# hib1p2 register map
Vendor: Texas Instruments
Peripheral module from a debugger description file (folder cc32).
Registers are 32-bit, read-write, no defined reset value unless marked. A register's access mark holds for its fields unless they carry their own. Offsets are as the file gives them; lines under a group give offsets from that group; [hi:lo] are bit positions; {n}, {i} and the like mark numbered series; 'fields as' and 'values as' point back to an identical list; <NAME> marks a mode.

## hib1p2
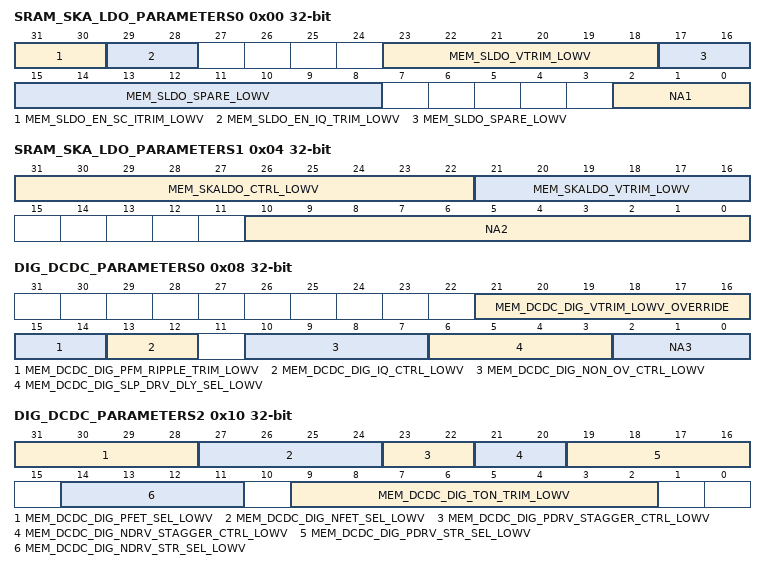
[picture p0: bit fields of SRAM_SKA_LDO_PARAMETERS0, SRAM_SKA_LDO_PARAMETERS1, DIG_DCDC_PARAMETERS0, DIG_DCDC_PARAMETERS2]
0x00 SRAM_SKA_LDO_PARAMETERS0
  [31:30] MEM_SLDO_EN_SC_ITRIM_LOWV, [29:28] MEM_SLDO_EN_IQ_TRIM_LOWV, [23:18] MEM_SLDO_VTRIM_LOWV, [17:8] MEM_SLDO_SPARE_LOWV, [2:0] NA1
0x04 SRAM_SKA_LDO_PARAMETERS1
  [31:22] MEM_SKALDO_CTRL_LOWV, [21:16] MEM_SKALDO_VTRIM_LOWV, [10:0] NA2
0x08 DIG_DCDC_PARAMETERS0
  [21:16] MEM_DCDC_DIG_VTRIM_LOWV_OVERRIDE — Override value for DCDC_DIG_VTRIM : Applicable only when bit [27] of DIG_DCDC_PARAMETERS1 [0x000C] is set to 1.
  [15:14] MEM_DCDC_DIG_PFM_RIPPLE_TRIM_LOWV
  [13:12] MEM_DCDC_DIG_IQ_CTRL_LOWV
  [10:7] MEM_DCDC_DIG_NON_OV_CTRL_LOWV
  [6:3] MEM_DCDC_DIG_SLP_DRV_DLY_SEL_LOWV
  [2:0] NA3
0x0C DIG_DCDC_PARAMETERS1
  [24:0] NA4
0x10 DIG_DCDC_PARAMETERS2
  [31:28] MEM_DCDC_DIG_PFET_SEL_LOWV, [27:24] MEM_DCDC_DIG_NFET_SEL_LOWV, [23:22] MEM_DCDC_DIG_PDRV_STAGGER_CTRL_LOWV, [21:20] MEM_DCDC_DIG_NDRV_STAGGER_CTRL_LOWV, [19:16] MEM_DCDC_DIG_PDRV_STR_SEL_LOWV, [14:11] MEM_DCDC_DIG_NDRV_STR_SEL_LOWV, [9:2] MEM_DCDC_DIG_TON_TRIM_LOWV
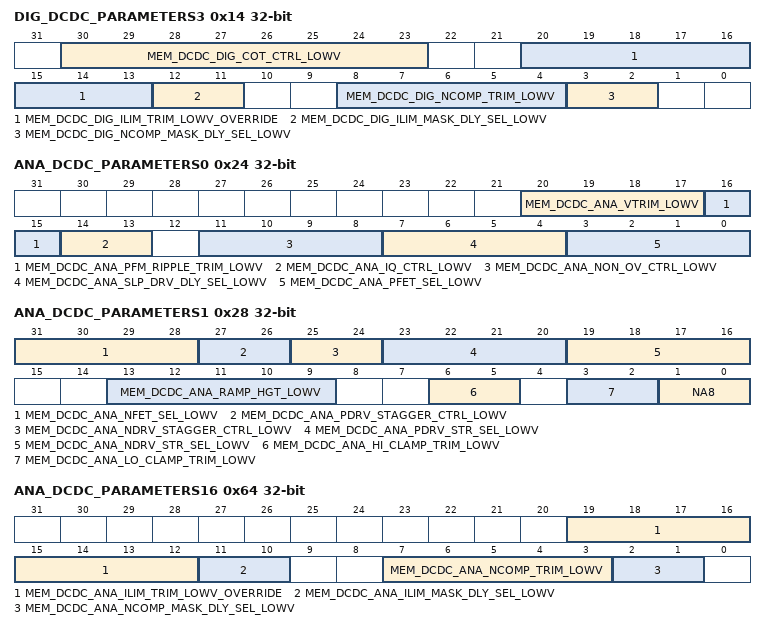
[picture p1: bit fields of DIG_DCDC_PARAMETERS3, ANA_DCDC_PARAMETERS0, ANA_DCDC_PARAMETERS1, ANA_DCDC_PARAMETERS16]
0x14 DIG_DCDC_PARAMETERS3
  [30:23] MEM_DCDC_DIG_COT_CTRL_LOWV
  [20:13] MEM_DCDC_DIG_ILIM_TRIM_LOWV_OVERRIDE — Override value for DCDC_DIG_ILIM_TRIM : Applicable only when bit [25] of DIG_DCDC_PARAMETERS1 [0x000C] is set to 1
  [12:11] MEM_DCDC_DIG_ILIM_MASK_DLY_SEL_LOWV
  [8:4] MEM_DCDC_DIG_NCOMP_TRIM_LOWV
  [3:2] MEM_DCDC_DIG_NCOMP_MASK_DLY_SEL_LOWV
0x18 DIG_DCDC_PARAMETERS4
  [28:0] NA7
0x1C DIG_DCDC_PARAMETERS5 access not given
0x20 DIG_DCDC_PARAMETERS6 access not given
0x24 ANA_DCDC_PARAMETERS0
  [20:17] MEM_DCDC_ANA_VTRIM_LOWV, [16:15] MEM_DCDC_ANA_PFM_RIPPLE_TRIM_LOWV, [14:13] MEM_DCDC_ANA_IQ_CTRL_LOWV, [11:8] MEM_DCDC_ANA_NON_OV_CTRL_LOWV, [7:4] MEM_DCDC_ANA_SLP_DRV_DLY_SEL_LOWV, [3:0] MEM_DCDC_ANA_PFET_SEL_LOWV
0x28 ANA_DCDC_PARAMETERS1
  [31:28] MEM_DCDC_ANA_NFET_SEL_LOWV, [27:26] MEM_DCDC_ANA_PDRV_STAGGER_CTRL_LOWV, [25:24] MEM_DCDC_ANA_NDRV_STAGGER_CTRL_LOWV, [23:20] MEM_DCDC_ANA_PDRV_STR_SEL_LOWV, [19:16] MEM_DCDC_ANA_NDRV_STR_SEL_LOWV, [13:9] MEM_DCDC_ANA_RAMP_HGT_LOWV, [6:5] MEM_DCDC_ANA_HI_CLAMP_TRIM_LOWV, [3:2] MEM_DCDC_ANA_LO_CLAMP_TRIM_LOWV, [1:0] NA8
0x64 ANA_DCDC_PARAMETERS16
  [19:12] MEM_DCDC_ANA_ILIM_TRIM_LOWV_OVERRIDE, [11:10] MEM_DCDC_ANA_ILIM_MASK_DLY_SEL_LOWV, [7:3] MEM_DCDC_ANA_NCOMP_TRIM_LOWV, [2:1] MEM_DCDC_ANA_NCOMP_MASK_DLY_SEL_LOWV
0x68 ANA_DCDC_PARAMETERS17
  [29:0] NA17
0x6C ANA_DCDC_PARAMETERS18 access not given
0x70 ANA_DCDC_PARAMETERS19 access not given
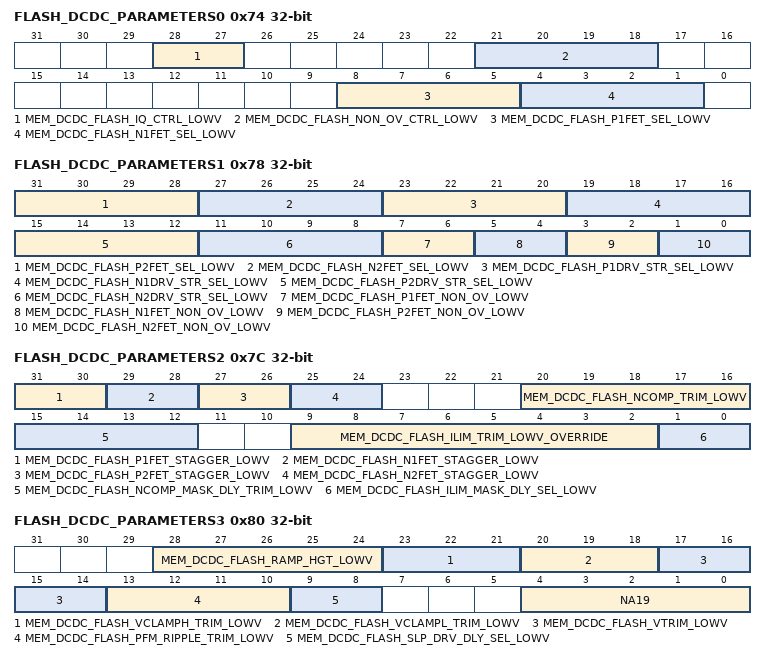
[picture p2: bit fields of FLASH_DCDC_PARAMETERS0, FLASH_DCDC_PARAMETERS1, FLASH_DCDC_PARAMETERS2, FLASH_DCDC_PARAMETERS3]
0x74 FLASH_DCDC_PARAMETERS0
  [28:27] MEM_DCDC_FLASH_IQ_CTRL_LOWV, [21:18] MEM_DCDC_FLASH_NON_OV_CTRL_LOWV, [8:5] MEM_DCDC_FLASH_P1FET_SEL_LOWV, [4:1] MEM_DCDC_FLASH_N1FET_SEL_LOWV
0x78 FLASH_DCDC_PARAMETERS1
  [31:28] MEM_DCDC_FLASH_P2FET_SEL_LOWV, [27:24] MEM_DCDC_FLASH_N2FET_SEL_LOWV, [23:20] MEM_DCDC_FLASH_P1DRV_STR_SEL_LOWV, [19:16] MEM_DCDC_FLASH_N1DRV_STR_SEL_LOWV, [15:12] MEM_DCDC_FLASH_P2DRV_STR_SEL_LOWV, [11:8] MEM_DCDC_FLASH_N2DRV_STR_SEL_LOWV, [7:6] MEM_DCDC_FLASH_P1FET_NON_OV_LOWV, [5:4] MEM_DCDC_FLASH_N1FET_NON_OV_LOWV, [3:2] MEM_DCDC_FLASH_P2FET_NON_OV_LOWV, [1:0] MEM_DCDC_FLASH_N2FET_NON_OV_LOWV
0x7C FLASH_DCDC_PARAMETERS2
  [31:30] MEM_DCDC_FLASH_P1FET_STAGGER_LOWV, [29:28] MEM_DCDC_FLASH_N1FET_STAGGER_LOWV, [27:26] MEM_DCDC_FLASH_P2FET_STAGGER_LOWV, [25:24] MEM_DCDC_FLASH_N2FET_STAGGER_LOWV, [20:16] MEM_DCDC_FLASH_NCOMP_TRIM_LOWV, [15:12] MEM_DCDC_FLASH_NCOMP_MASK_DLY_TRIM_LOWV, [9:2] MEM_DCDC_FLASH_ILIM_TRIM_LOWV_OVERRIDE, [1:0] MEM_DCDC_FLASH_ILIM_MASK_DLY_SEL_LOWV
0x80 FLASH_DCDC_PARAMETERS3
  [28:24] MEM_DCDC_FLASH_RAMP_HGT_LOWV, [23:21] MEM_DCDC_FLASH_VCLAMPH_TRIM_LOWV, [20:18] MEM_DCDC_FLASH_VCLAMPL_TRIM_LOWV, [17:14] MEM_DCDC_FLASH_VTRIM_LOWV, [13:10] MEM_DCDC_FLASH_PFM_RIPPLE_TRIM_LOWV, [9:8] MEM_DCDC_FLASH_SLP_DRV_DLY_SEL_LOWV, [4:0] NA19
0x84 FLASH_DCDC_PARAMETERS4 access not given
0x88 FLASH_DCDC_PARAMETERS5 access not given
0x8C FLASH_DCDC_PARAMETERS6
  [29:0] NA20
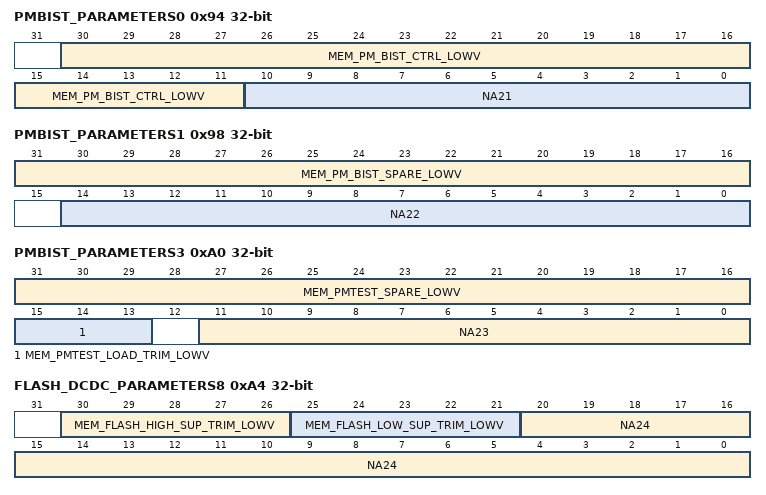
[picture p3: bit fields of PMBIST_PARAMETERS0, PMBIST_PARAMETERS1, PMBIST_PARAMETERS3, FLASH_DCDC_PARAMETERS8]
0x94 PMBIST_PARAMETERS0
  [30:11] MEM_PM_BIST_CTRL_LOWV, [10:0] NA21
0x98 PMBIST_PARAMETERS1
  [31:16] MEM_PM_BIST_SPARE_LOWV, [14:0] NA22
0x9C PMBIST_PARAMETERS2 access not given
0xA0 PMBIST_PARAMETERS3
  [31:16] MEM_PMTEST_SPARE_LOWV, [15:13] MEM_PMTEST_LOAD_TRIM_LOWV, [11:0] NA23
0xA4 FLASH_DCDC_PARAMETERS8
  [30:26] MEM_FLASH_HIGH_SUP_TRIM_LOWV, [25:21] MEM_FLASH_LOW_SUP_TRIM_LOWV, [20:0] NA24
0xA8 ANA_DCDC_PARAMETERS_OVERRIDE access not given
0xAC FLASH_DCDC_PARAMETERS_OVERRIDE access not given
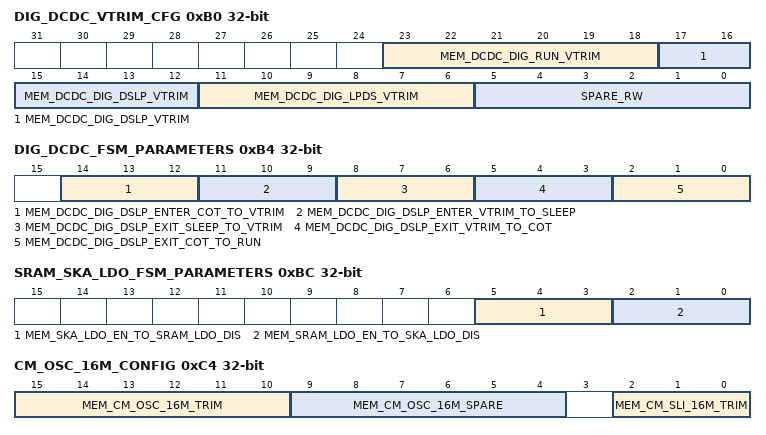
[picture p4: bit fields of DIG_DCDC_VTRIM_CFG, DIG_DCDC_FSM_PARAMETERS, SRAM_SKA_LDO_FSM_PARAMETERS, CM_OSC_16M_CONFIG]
0xB0 DIG_DCDC_VTRIM_CFG
  [23:18] MEM_DCDC_DIG_RUN_VTRIM, [17:12] MEM_DCDC_DIG_DSLP_VTRIM, [11:6] MEM_DCDC_DIG_LPDS_VTRIM, [5:0] SPARE_RW
0xB4 DIG_DCDC_FSM_PARAMETERS
  [14:12] MEM_DCDC_DIG_DSLP_ENTER_COT_TO_VTRIM, [11:9] MEM_DCDC_DIG_DSLP_ENTER_VTRIM_TO_SLEEP, [8:6] MEM_DCDC_DIG_DSLP_EXIT_SLEEP_TO_VTRIM, [5:3] MEM_DCDC_DIG_DSLP_EXIT_VTRIM_TO_COT, [2:0] MEM_DCDC_DIG_DSLP_EXIT_COT_TO_RUN
0xB8 ANA_DCDC_FSM_PARAMETERS
  [2:0] MEM_DCDC_ANA_DSLP_EXIT_SLEEP_TO_RUN
0xBC SRAM_SKA_LDO_FSM_PARAMETERS
  [5:3] MEM_SKA_LDO_EN_TO_SRAM_LDO_DIS, [2:0] MEM_SRAM_LDO_EN_TO_SKA_LDO_DIS
0xC0 BGAP_DUTY_CYCLING_EXIT_CFG
  [2:0] MEM_BGAP_DUTY_CYCLING_EXIT_TIME
0xC4 CM_OSC_16M_CONFIG
  [15:10] MEM_CM_OSC_16M_TRIM, [9:4] MEM_CM_OSC_16M_SPARE, [2:0] MEM_CM_SLI_16M_TRIM
0xC8 SOP_SENSE_VALUE
  [7:0] SOP_SENSE_VALUE
0xCC HIB_RTC_TIMER_LSW_1P2 access not given
0xD0 HIB_RTC_TIMER_MSW_1P2
  [15:0] HIB_RTC_TIMER_MSW
0xD4 BGAP_TRIM_OVERRIDES access not given
0xD8 EFUSE_READ_REG0 access not given
0xDC EFUSE_READ_REG1 access not given
0xE0 POR_TEST_CTRL access not given
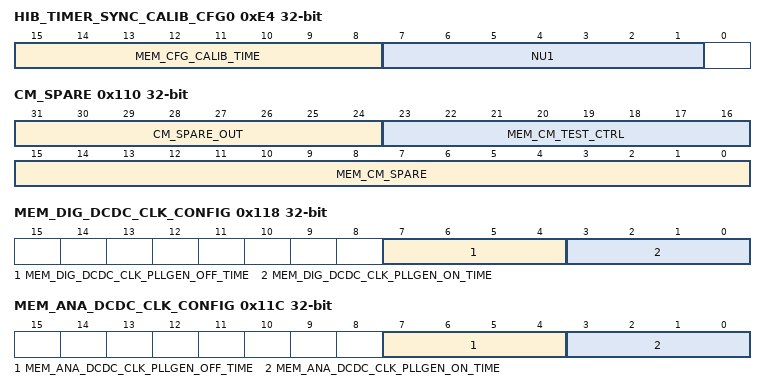
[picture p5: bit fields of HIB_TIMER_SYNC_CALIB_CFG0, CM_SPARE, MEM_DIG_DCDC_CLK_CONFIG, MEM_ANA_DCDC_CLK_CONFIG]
0xE4 HIB_TIMER_SYNC_CALIB_CFG0
  [15:8] MEM_CFG_CALIB_TIME, [7:1] NU1
0xE8 HIB_TIMER_SYNC_CALIB_CFG1
  [19:0] FAST_CALIB_COUNT
0xEC HIB_TIMER_SYNC_CFG2
  [7:2] NU1
0xF0 HIB_TIMER_SYNC_TSF_ADJ_VAL access not given
0xF4 HIB_TIMER_RTC_GTS_TIMESTAMP_LSW access not given
0xF8 HIB_TIMER_RTC_GTS_TIMESTAMP_MSW
  [15:0] RTC_GTS_TIMESTAMP_MSW
0xFC HIB_TIMER_RTC_WUP_TIMESTAMP_LSW access not given
0x100 HIB_TIMER_RTC_WUP_TIMESTAMP_MSW
  [15:0] RTC_WUP_TIMESTAMP_MSW
0x104 HIB_TIMER_SYNC_WAKE_OFFSET_ERR
  [11:0] WUP_OFFSET_ERROR
0x108 HIB_TIMER_SYNC_TSF_CURR_VAL_LSW access not given
0x10C HIB_TIMER_SYNC_TSF_CURR_VAL_MSW access not given
0x110 CM_SPARE
  [31:24] CM_SPARE_OUT, [23:16] MEM_CM_TEST_CTRL, [15:0] MEM_CM_SPARE
0x114 PORPOL_SPARE access not given
0x118 MEM_DIG_DCDC_CLK_CONFIG
  [7:4] MEM_DIG_DCDC_CLK_PLLGEN_OFF_TIME, [3:0] MEM_DIG_DCDC_CLK_PLLGEN_ON_TIME
0x11C MEM_ANA_DCDC_CLK_CONFIG
  [7:4] MEM_ANA_DCDC_CLK_PLLGEN_OFF_TIME, [3:0] MEM_ANA_DCDC_CLK_PLLGEN_ON_TIME
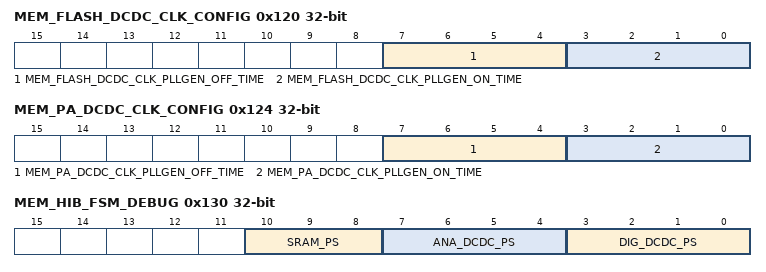
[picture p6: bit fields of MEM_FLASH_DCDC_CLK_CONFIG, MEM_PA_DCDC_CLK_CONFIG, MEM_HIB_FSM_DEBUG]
0x120 MEM_FLASH_DCDC_CLK_CONFIG
  [7:4] MEM_FLASH_DCDC_CLK_PLLGEN_OFF_TIME, [3:0] MEM_FLASH_DCDC_CLK_PLLGEN_ON_TIME
0x124 MEM_PA_DCDC_CLK_CONFIG
  [7:4] MEM_PA_DCDC_CLK_PLLGEN_OFF_TIME, [3:0] MEM_PA_DCDC_CLK_PLLGEN_ON_TIME
0x128 MEM_SLDO_VNWA_OVERRIDE access not given
0x12C MEM_BGAP_DUTY_CYCLING_ENABLE_OVERRIDE access not given
0x130 MEM_HIB_FSM_DEBUG
  [10:8] SRAM_PS, [7:4] ANA_DCDC_PS, [3:0] DIG_DCDC_PS
0x134 MEM_SLDO_VNWA_SW_CTRL
  [19:0] MEM_SLDO_VNWA_SW_CTRL
0x138 MEM_SLDO_WEAK_PROCESS access not given
0x13C MEM_PA_DCDC_OV_UV_STATUS access not given
0x140 MEM_CM_TEST_MODE access not given
